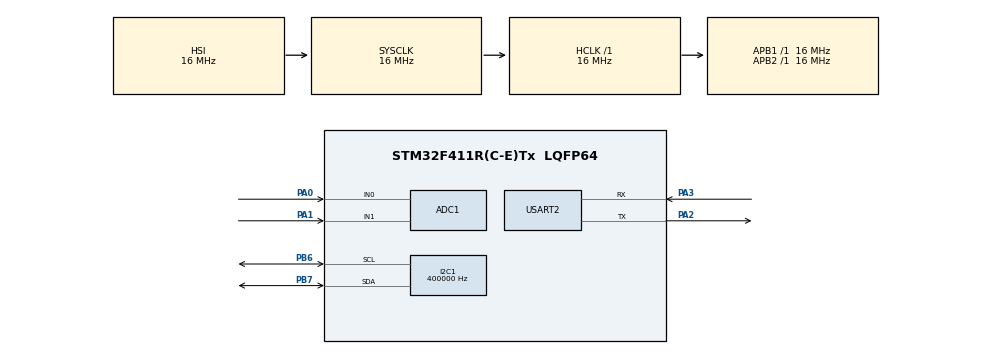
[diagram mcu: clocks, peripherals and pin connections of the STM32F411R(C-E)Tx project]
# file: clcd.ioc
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ADC1.Channel-0\#ChannelRegularConversion=ADC_CHANNEL_0
ADC1.Channel-1\#ChannelRegularConversion=ADC_CHANNEL_1
ADC1.ClockPrescaler=ADC_CLOCK_SYNC_PCLK_DIV6
ADC1.ContinuousConvMode=ENABLE
ADC1.DMAContinuousRequests=ENABLE
ADC1.DiscontinuousConvMode=DISABLE
ADC1.NbrOfConversion=2
ADC1.NbrOfConversionFlag=1
ADC1.Rank-0\#ChannelRegularConversion=1
ADC1.Rank-1\#ChannelRegularConversion=2
ADC1.SamplingTime-0\#ChannelRegularConversion=ADC_SAMPLETIME_84CYCLES
ADC1.SamplingTime-1\#ChannelRegularConversion=ADC_SAMPLETIME_84CYCLES
ADC1.ScanConvMode=ENABLE
ADC1.master=1
Dma.ADC1.0.Direction=DMA_PERIPH_TO_MEMORY
Dma.ADC1.0.FIFOMode=DMA_FIFOMODE_DISABLE
Dma.ADC1.0.Instance=DMA2_Stream0
Dma.ADC1.0.MemDataAlignment=DMA_MDATAALIGN_HALFWORD
Dma.ADC1.0.MemInc=DMA_MINC_ENABLE
Dma.ADC1.0.Mode=DMA_CIRCULAR
Dma.ADC1.0.PeriphDataAlignment=DMA_PDATAALIGN_HALFWORD
Dma.ADC1.0.PeriphInc=DMA_PINC_DISABLE
Dma.ADC1.0.Priority=DMA_PRIORITY_LOW
Dma.Request0=ADC1
I2C1.ClockSpeed=400000
I2C1.I2C_Mode=I2C_Fast
Mcu.Family=STM32F4
Mcu.Name=STM32F411R(C-E)Tx
Mcu.Package=LQFP64
NVIC.DMA2_Stream0_IRQn=true\:0\:0\:false\:false\:true\:false\:true\:true
NVIC.PriorityGroup=NVIC_PRIORITYGROUP_4
NVIC.USART2_IRQn=true\:0\:0\:false\:false\:true\:true\:true\:true
PA0-WKUP.Signal=ADCx_IN0
PA1.Signal=ADCx_IN1
PA2.Mode=Asynchronous
PA2.Signal=USART2_TX
PA3.Mode=Asynchronous
PA3.Signal=USART2_RX
PB6.GPIO_Pu=GPIO_PULLUP
PB6.Mode=I2C
PB6.Signal=I2C1_SCL
PB7.GPIO_Pu=GPIO_PULLUP
PB7.Mode=I2C
PB7.Signal=I2C1_SDA
ProjectManager.HeapSize=0x200
ProjectManager.StackSize=0x400
ProjectManager.TargetToolchain=STM32CubeIDE
RCC.AHBFreq_Value=16000000
RCC.APB1Freq_Value=16000000
RCC.APB2Freq_Value=16000000
RCC.CortexFreq_Value=16000000
RCC.HSE_VALUE=25000000
RCC.HSI_VALUE=16000000
RCC.LSE_VALUE=32768
RCC.SYSCLKFreq_VALUE=16000000
RCC.VCOOutputFreq_Value=192000000
SH.ADCx_IN0.0=ADC1_IN0,IN0
SH.ADCx_IN1.0=ADC1_IN1,IN1
USART2.VirtualMode=VM_ASYNC
board=custom

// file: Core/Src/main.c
/* USER CODE BEGIN Header */
/**
  ******************************************************************************
  * @file           : main.c
  * @brief          : Main program body
  ******************************************************************************
  * @attention
  *
  * Copyright (c) 2024 STMicroelectronics.
  * All rights reserved.
  *
  * This software is licensed under terms that can be found in the LICENSE file
  * in the root directory of this software component.
  * If no LICENSE file comes with this software, it is provided AS-IS.
  *
  ******************************************************************************
  */
/* USER CODE END Header */
#include "main.h"

/* USER CODE BEGIN Includes */
#include "uart.h"
#include "I2C_CLCD.h"
/* USER CODE END Includes */

ADC_HandleTypeDef hadc1;
DMA_HandleTypeDef hdma_adc1;

I2C_HandleTypeDef hi2c1;

UART_HandleTypeDef huart2;

void SystemClock_Config(void);
static void MX_GPIO_Init(void);
static void MX_DMA_Init(void);
static void MX_I2C1_Init(void);
static void MX_USART2_UART_Init(void);
static void MX_ADC1_Init(void);

int main(void)
{

  /* MCU Configuration--------------------------------------------------------*/

  /* Reset of all peripherals, Initializes the Flash interface and the Systick. */
  HAL_Init();

  /* Configure the system clock */
  SystemClock_Config();

  /* Initialize all configured peripherals */
  MX_GPIO_Init();
  MX_DMA_Init();
  MX_I2C1_Init();
  MX_USART2_UART_Init();
  MX_ADC1_Init();
  /* USER CODE BEGIN 2 */
   initUart(&huart2);

   printf("i2c scan start\n");
   for(int Address = 0; Address < 256; Address++)	{
  	 if(HAL_I2C_IsDeviceReady(&hi2c1, Address, 0, 10) == HAL_OK)	{
  		 printf("%02x is ready\n", Address);
  	 }
	}
	printf("i2c scan end\n");

	I2C_CLCD_init();
	I2C_CLCD_GotoXY(0, 0);
	I2C_CLCD_PutStr("                ");
	I2C_CLCD_GotoXY(0, 1);
	I2C_CLCD_PutStr("                ");
	I2C_CLCD_GotoXY(0, 0);
	I2C_CLCD_CustomFont();

//   //	Setup ADC
//	uint16_t adcValue[2];
//	HAL_ADC_Start_DMA(&hadc1, (uint32_t*) adcValue, 2);
//
//	I2C_CLCD_GotoXY(0, 0);
//	I2C_CLCD_PutC(0);
//	I2C_CLCD_PutC(1);
//	I2C_CLCD_PutC(2);
//	I2C_CLCD_PutC(3);
//	I2C_CLCD_GotoXY(0, 1);
//	I2C_CLCD_PutC(4);
//	I2C_CLCD_PutC(5);
//	I2C_CLCD_PutC(6);
//	I2C_CLCD_PutC(7);
//	I2C_CLCD_CG_Update();
//	/* USER CODE END 2 */

	/* Infinite loop */
	/* USER CODE BEGIN WHILE */
	while (1) {
//		I2C_CLCD_CG_ScrollLeft();
//		I2C_CLCD_CG_DrawPixel(19, 15 - (adcValue[0] / 273));
//		I2C_CLCD_CG_Update();
//		I2C_CLCD_GotoXY(5, 0);
//		char str[20];
//		sprintf(str, "%5d", adcValue[0]);
//		I2C_CLCD_PutStr(str);

		// Under : DMA
		// Setup ADC

		// Under : Polling
//  	//	1-Cycle : HAL_ADC_Start ~ HAL_ADC_Stop
//  	//	Conversion A0 : 0 ~ 4095
//  	HAL_ADC_Start(&hadc1);
//		HAL_ADC_PollForConversion(&hadc1, 10);							// Waitinf for AD conversion
//		uint16_t adcValue1 = HAL_ADC_GetValue(&hadc1);
//
//		//	Conversion A1
//		HAL_ADC_PollForConversion(&hadc1, 10);
//		uint16_t adcValue2 = HAL_ADC_GetValue(&hadc1);
//		HAL_ADC_Stop(&hadc1);

		//	Present LCD
//		I2C_CLCD_Progressbar(adcValue[0]/51, 0);		//  channel 0
//		I2C_CLCD_Progressbar(adcValue[1]/51, 1);		//	channel 1
		HAL_Delay(50);

		// CLCD Example
//     static int count = 0;
//     I2C_CLCD_Progressbar(count);
//     count++;
//     count %= 81;
//     HAL_Delay(50);
    /* USER CODE END WHILE */

  }
}

void SystemClock_Config(void)
{
  RCC_OscInitTypeDef RCC_OscInitStruct = {0};
  RCC_ClkInitTypeDef RCC_ClkInitStruct = {0};

  /** Configure the main internal regulator output voltage
  */
  __HAL_RCC_PWR_CLK_ENABLE();
  __HAL_PWR_VOLTAGESCALING_CONFIG(PWR_REGULATOR_VOLTAGE_SCALE1);

  /** Initializes the RCC Oscillators according to the specified parameters
  * in the RCC_OscInitTypeDef structure.
  */
  RCC_OscInitStruct.OscillatorType = RCC_OSCILLATORTYPE_HSI;
  RCC_OscInitStruct.HSIState = RCC_HSI_ON;
  RCC_OscInitStruct.HSICalibrationValue = RCC_HSICALIBRATION_DEFAULT;
  RCC_OscInitStruct.PLL.PLLState = RCC_PLL_NONE;
  if (HAL_RCC_OscConfig(&RCC_OscInitStruct) != HAL_OK)
  {
    Error_Handler();
  }

  /** Initializes the CPU, AHB and APB buses clocks
  */
  RCC_ClkInitStruct.ClockType = RCC_CLOCKTYPE_HCLK|RCC_CLOCKTYPE_SYSCLK
                              |RCC_CLOCKTYPE_PCLK1|RCC_CLOCKTYPE_PCLK2;
  RCC_ClkInitStruct.SYSCLKSource = RCC_SYSCLKSOURCE_HSI;
  RCC_ClkInitStruct.AHBCLKDivider = RCC_SYSCLK_DIV1;
  RCC_ClkInitStruct.APB1CLKDivider = RCC_HCLK_DIV1;
  RCC_ClkInitStruct.APB2CLKDivider = RCC_HCLK_DIV1;

  if (HAL_RCC_ClockConfig(&RCC_ClkInitStruct, FLASH_LATENCY_0) != HAL_OK)
  {
    Error_Handler();
  }
}

static void MX_ADC1_Init(void)
{

  ADC_ChannelConfTypeDef sConfig = {0};

  /** Configure the global features of the ADC (Clock, Resolution, Data Alignment and number of conversion)
  */
  hadc1.Instance = ADC1;
  hadc1.Init.ClockPrescaler = ADC_CLOCK_SYNC_PCLK_DIV2;
  hadc1.Init.Resolution = ADC_RESOLUTION_12B;
  hadc1.Init.ScanConvMode = ENABLE;
  hadc1.Init.ContinuousConvMode = ENABLE;
  hadc1.Init.DiscontinuousConvMode = DISABLE;
  hadc1.Init.ExternalTrigConvEdge = ADC_EXTERNALTRIGCONVEDGE_NONE;
  hadc1.Init.ExternalTrigConv = ADC_SOFTWARE_START;
  hadc1.Init.DataAlign = ADC_DATAALIGN_RIGHT;
  hadc1.Init.NbrOfConversion = 2;
  hadc1.Init.DMAContinuousRequests = ENABLE;
  hadc1.Init.EOCSelection = ADC_EOC_SINGLE_CONV;
  if (HAL_ADC_Init(&hadc1) != HAL_OK)
  {
    Error_Handler();
  }

  /** Configure for the selected ADC regular channel its corresponding rank in the sequencer and its sample time.
  */
  sConfig.Channel = ADC_CHANNEL_0;
  sConfig.Rank = 1;
  sConfig.SamplingTime = ADC_SAMPLETIME_84CYCLES;
  if (HAL_ADC_ConfigChannel(&hadc1, &sConfig) != HAL_OK)
  {
    Error_Handler();
  }

  /** Configure for the selected ADC regular channel its corresponding rank in the sequencer and its sample time.
  */
  sConfig.Channel = ADC_CHANNEL_1;
  sConfig.Rank = 2;
  if (HAL_ADC_ConfigChannel(&hadc1, &sConfig) != HAL_OK)
  {
    Error_Handler();
  }

}

static void MX_I2C1_Init(void)
{

  hi2c1.Instance = I2C1;
  hi2c1.Init.ClockSpeed = 400000;
  hi2c1.Init.DutyCycle = I2C_DUTYCYCLE_2;
  hi2c1.Init.OwnAddress1 = 0;
  hi2c1.Init.AddressingMode = I2C_ADDRESSINGMODE_7BIT;
  hi2c1.Init.DualAddressMode = I2C_DUALADDRESS_DISABLE;
  hi2c1.Init.OwnAddress2 = 0;
  hi2c1.Init.GeneralCallMode = I2C_GENERALCALL_DISABLE;
  hi2c1.Init.NoStretchMode = I2C_NOSTRETCH_DISABLE;
  if (HAL_I2C_Init(&hi2c1) != HAL_OK)
  {
    Error_Handler();
  }

}

static void MX_USART2_UART_Init(void)
{

  huart2.Instance = USART2;
  huart2.Init.BaudRate = 115200;
  huart2.Init.WordLength = UART_WORDLENGTH_8B;
  huart2.Init.StopBits = UART_STOPBITS_1;
  huart2.Init.Parity = UART_PARITY_NONE;
  huart2.Init.Mode = UART_MODE_TX_RX;
  huart2.Init.HwFlowCtl = UART_HWCONTROL_NONE;
  huart2.Init.OverSampling = UART_OVERSAMPLING_16;
  if (HAL_UART_Init(&huart2) != HAL_OK)
  {
    Error_Handler();
  }

}

static void MX_DMA_Init(void)
{

  /* DMA controller clock enable */
  __HAL_RCC_DMA2_CLK_ENABLE();

  /* DMA interrupt init */
  /* DMA2_Stream0_IRQn interrupt configuration */
  HAL_NVIC_SetPriority(DMA2_Stream0_IRQn, 0, 0);
  HAL_NVIC_EnableIRQ(DMA2_Stream0_IRQn);

}

static void MX_GPIO_Init(void)
{

  /* GPIO Ports Clock Enable */
  __HAL_RCC_GPIOA_CLK_ENABLE();
  __HAL_RCC_GPIOB_CLK_ENABLE();

}

void Error_Handler(void)
{
  __disable_irq();
  while (1)
  {
  }
}
